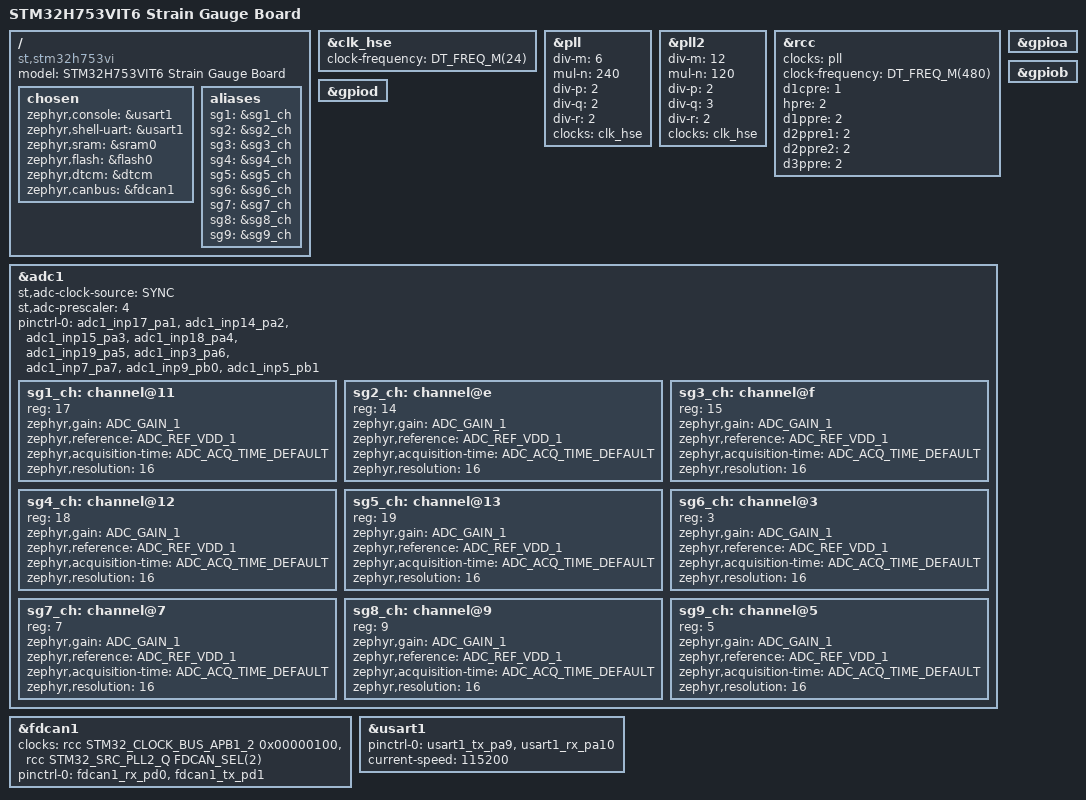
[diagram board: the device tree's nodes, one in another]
/*
 * STM32H753VIT6 Strain Gauge Board
 * 9 ADC channels + FDCAN1
 * SG10 (PB2) is physically wired but not ADC-capable on H753VIT6.
 */

/dts-v1/;

#include <st/h7/stm32h753Xi.dtsi>
#include <st/h7/stm32h753vitx-pinctrl.dtsi>
#include <zephyr/dt-bindings/adc/adc.h>

/ {
	model = "STM32H753VIT6 Strain Gauge Board";
	compatible = "st,stm32h753vi";

	chosen {
		zephyr,console = &usart1;
		zephyr,shell-uart = &usart1;
		zephyr,sram = &sram0;
		zephyr,flash = &flash0;
		zephyr,dtcm = &dtcm;
		zephyr,canbus = &fdcan1;
	};

	aliases {
		sg1 = &sg1_ch;
		sg2 = &sg2_ch;
		sg3 = &sg3_ch;
		sg4 = &sg4_ch;
		sg5 = &sg5_ch;
		sg6 = &sg6_ch;
		sg7 = &sg7_ch;
		sg8 = &sg8_ch;
		sg9 = &sg9_ch;
	};
};

/* ---------- Clock tree ---------- */

&clk_hse {
	clock-frequency = <DT_FREQ_M(24)>;
	status = "okay";
};

&pll {
	div-m = <6>;
	mul-n = <240>;
	div-p = <2>;
	div-q = <2>;
	div-r = <2>;
	clocks = <&clk_hse>;
	status = "okay";
};

&pll2 {
	div-m = <12>;
	mul-n = <120>;
	div-p = <2>;
	div-q = <3>;
	div-r = <2>;
	clocks = <&clk_hse>;
	status = "okay";
};

&rcc {
	clocks = <&pll>;
	clock-frequency = <DT_FREQ_M(480)>;

	d1cpre = <1>;
	hpre = <2>;
	d1ppre = <2>;
	d2ppre1 = <2>;
	d2ppre2 = <2>;
	d3ppre = <2>;
};

/* ---------- GPIO ---------- */

&gpioa { status = "okay"; };
&gpiob { status = "okay"; };
&gpiod { status = "okay"; };

/* ---------- ADC ---------- */

&adc1 {
	#address-cells = <1>;
	#size-cells = <0>;
	#io-channel-cells = <1>;

	st,adc-clock-source = "SYNC";
	st,adc-prescaler = <4>;

	status = "okay";

	pinctrl-0 = <
		&adc1_inp17_pa1    /* SG1 */
		&adc1_inp14_pa2    /* SG2 */
		&adc1_inp15_pa3    /* SG3 */
		&adc1_inp18_pa4    /* SG4 */
		&adc1_inp19_pa5    /* SG5 */
		&adc1_inp3_pa6     /* SG6 */
		&adc1_inp7_pa7     /* SG7 */
		&adc1_inp9_pb0     /* SG8 */
		&adc1_inp5_pb1     /* SG9 */
	>;
	pinctrl-names = "default";

	/* NOTE THAT THE CHANNEL IDENTIFIER (reg) IS HEX EG #11=0dx17 */

	/* PA1 = ADC1_INP17 */
	sg1_ch: channel@11 {
		reg = <17>;
		zephyr,gain = "ADC_GAIN_1";
		zephyr,reference = "ADC_REF_VDD_1";
		zephyr,acquisition-time = <ADC_ACQ_TIME_DEFAULT>;
		zephyr,resolution = <16>;
	};

	/* PA2 = ADC12_INP14 */
	sg2_ch: channel@e {
		reg = <14>;
		zephyr,gain = "ADC_GAIN_1";
		zephyr,reference = "ADC_REF_VDD_1";
		zephyr,acquisition-time = <ADC_ACQ_TIME_DEFAULT>;
		zephyr,resolution = <16>;
	};

	/* PA3 = ADC12_INP15 */
	sg3_ch: channel@f {
		reg = <15>;
		zephyr,gain = "ADC_GAIN_1";
		zephyr,reference = "ADC_REF_VDD_1";
		zephyr,acquisition-time = <ADC_ACQ_TIME_DEFAULT>;
		zephyr,resolution = <16>;
	};

	/* PA4 = ADC12_INP18 */
	sg4_ch: channel@12 {
		reg = <18>;
		zephyr,gain = "ADC_GAIN_1";
		zephyr,reference = "ADC_REF_VDD_1";
		zephyr,acquisition-time = <ADC_ACQ_TIME_DEFAULT>;
		zephyr,resolution = <16>;
	};

	/* PA5 = ADC12_INP19 */
	sg5_ch: channel@13 {
		reg = <19>;
		zephyr,gain = "ADC_GAIN_1";
		zephyr,reference = "ADC_REF_VDD_1";
		zephyr,acquisition-time = <ADC_ACQ_TIME_DEFAULT>;
		zephyr,resolution = <16>;
	};

	/* PA6 = ADC12_INP3 */
	sg6_ch: channel@3 {
		reg = <3>;
		zephyr,gain = "ADC_GAIN_1";
		zephyr,reference = "ADC_REF_VDD_1";
		zephyr,acquisition-time = <ADC_ACQ_TIME_DEFAULT>;
		zephyr,resolution = <16>;
	};

	/* PA7 = ADC12_INP7 */
	sg7_ch: channel@7 {
		reg = <7>;
		zephyr,gain = "ADC_GAIN_1";
		zephyr,reference = "ADC_REF_VDD_1";
		zephyr,acquisition-time = <ADC_ACQ_TIME_DEFAULT>;
		zephyr,resolution = <16>;
	};

	/* PB0 = ADC12_INP9 */
	sg8_ch: channel@9 {
		reg = <9>;
		zephyr,gain = "ADC_GAIN_1";
		zephyr,reference = "ADC_REF_VDD_1";
		zephyr,acquisition-time = <ADC_ACQ_TIME_DEFAULT>;
		zephyr,resolution = <16>;
	};

	/* PB1 = ADC12_INP5 */
	sg9_ch: channel@5 {
		reg = <5>;
		zephyr,gain = "ADC_GAIN_1";
		zephyr,reference = "ADC_REF_VDD_1";
		zephyr,acquisition-time = <ADC_ACQ_TIME_DEFAULT>;
		zephyr,resolution = <16>;
	};
};

/* ---------- FDCAN ---------- */

&fdcan1 {
	clocks = <&rcc STM32_CLOCK_BUS_APB1_2 0x00000100>,
		 <&rcc STM32_SRC_PLL2_Q FDCAN_SEL(2)>;

	pinctrl-0 = <&fdcan1_rx_pd0 &fdcan1_tx_pd1>;
	pinctrl-names = "default";

	status = "okay";
};

/* ---------- USART (console) ---------- */

&usart1 {
	pinctrl-0 = <&usart1_tx_pa9 &usart1_rx_pa10>;
	pinctrl-names = "default";
	current-speed = <115200>;
	status = "okay";
};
